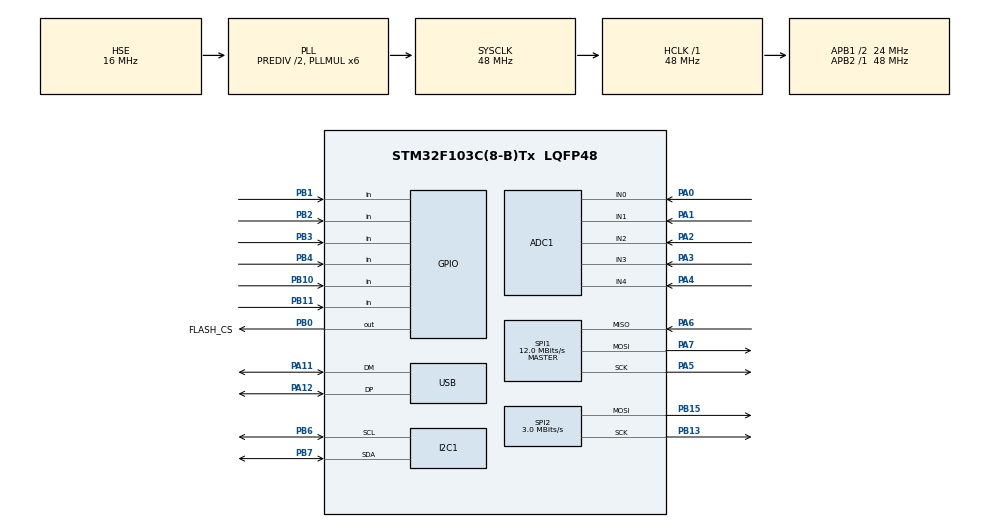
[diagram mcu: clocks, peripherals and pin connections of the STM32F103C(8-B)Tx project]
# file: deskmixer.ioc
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ADC1.Channel-0\#ChannelRegularConversion=ADC_CHANNEL_0
ADC1.NbrOfConversionFlag=1
ADC1.Rank-0\#ChannelRegularConversion=1
ADC1.SamplingTime-0\#ChannelRegularConversion=ADC_SAMPLETIME_1CYCLE_5
ADC1.master=1
Dma.Request0=SPI2_TX
Dma.SPI2_TX.0.Direction=DMA_MEMORY_TO_PERIPH
Dma.SPI2_TX.0.Instance=DMA1_Channel5
Dma.SPI2_TX.0.MemDataAlignment=DMA_MDATAALIGN_BYTE
Dma.SPI2_TX.0.MemInc=DMA_MINC_ENABLE
Dma.SPI2_TX.0.Mode=DMA_NORMAL
Dma.SPI2_TX.0.PeriphDataAlignment=DMA_PDATAALIGN_BYTE
Dma.SPI2_TX.0.PeriphInc=DMA_PINC_DISABLE
Dma.SPI2_TX.0.Priority=DMA_PRIORITY_LOW
Mcu.Family=STM32F1
Mcu.Name=STM32F103C(8-B)Tx
Mcu.Package=LQFP48
NVIC.DMA1_Channel5_IRQn=true\:0\:0\:false\:false\:true\:false\:true\:true
NVIC.PriorityGroup=NVIC_PRIORITYGROUP_4
NVIC.USB_LP_CAN1_RX0_IRQn=true\:0\:0\:false\:false\:true\:false\:true\:true
PA0-WKUP.Signal=ADCx_IN0
PA1.Signal=ADCx_IN1
PA11.Mode=Device
PA11.Signal=USB_DM
PA12.Mode=Device
PA12.Signal=USB_DP
PA13.Mode=Serial_Wire
PA13.Signal=SYS_JTMS-SWDIO
PA14.Mode=Serial_Wire
PA14.Signal=SYS_JTCK-SWCLK
PA2.Signal=ADCx_IN2
PA3.Signal=ADCx_IN3
PA4.Signal=ADCx_IN4
PA5.Mode=Full_Duplex_Master
PA5.Signal=SPI1_SCK
PA6.Mode=Full_Duplex_Master
PA6.Signal=SPI1_MISO
PA7.Mode=Full_Duplex_Master
PA7.Signal=SPI1_MOSI
PB0.GPIO_Label=FLASH_CS
PB0.PinState=GPIO_PIN_SET
PB0.Signal=GPIO_Output
PB1.GPIO_PuPd=GPIO_PULLUP
PB1.Signal=GPIO_Input
PB10.GPIO_PuPd=GPIO_PULLUP
PB10.Signal=GPIO_Input
PB11.GPIO_PuPd=GPIO_PULLUP
PB11.Signal=GPIO_Input
PB13.Mode=TX_Only_Simplex_Unidirect_Master
PB13.Signal=SPI2_SCK
PB15.Mode=TX_Only_Simplex_Unidirect_Master
PB15.Signal=SPI2_MOSI
PB2.GPIO_PuPd=GPIO_PULLUP
PB2.Signal=GPIO_Input
PB3.GPIO_PuPd=GPIO_PULLUP
PB3.Signal=GPIO_Input
PB4.GPIO_PuPd=GPIO_PULLUP
PB4.Signal=GPIO_Input
PB6.Mode=I2C
PB6.Signal=I2C1_SCL
PB7.Mode=I2C
PB7.Signal=I2C1_SDA
PD0-OSC_IN.Mode=HSE-External-Oscillator
PD0-OSC_IN.Signal=RCC_OSC_IN
PD1-OSC_OUT.Mode=HSE-External-Oscillator
PD1-OSC_OUT.Signal=RCC_OSC_OUT
ProjectManager.HeapSize=0x200
ProjectManager.StackSize=0x400
ProjectManager.TargetToolchain=STM32CubeIDE
RCC.ADCPresc=RCC_ADCPCLK2_DIV4
RCC.AHBFreq_Value=48000000
RCC.APB1CLKDivider=RCC_HCLK_DIV2
RCC.APB1Freq_Value=24000000
RCC.APB1TimFreq_Value=48000000
RCC.APB2Freq_Value=48000000
RCC.APB2TimFreq_Value=48000000
RCC.HCLKFreq_Value=48000000
RCC.HSEDivPLL=RCC_HSE_PREDIV_DIV2
RCC.HSE_VALUE=16000000
RCC.PLLMUL=RCC_PLL_MUL6
RCC.SYSCLKFreq_VALUE=48000000
RCC.SYSCLKSource=RCC_SYSCLKSOURCE_PLLCLK
RCC.USBFreq_Value=48000000
SH.ADCx_IN0.0=ADC1_IN0,IN0
SH.ADCx_IN1.0=ADC1_IN1,IN1
SH.ADCx_IN2.0=ADC1_IN2,IN2
SH.ADCx_IN3.0=ADC1_IN3,IN3
SH.ADCx_IN4.0=ADC1_IN4,IN4
SPI1.BaudRatePrescaler=SPI_BAUDRATEPRESCALER_4
SPI1.CalculateBaudRate=12.0 MBits/s
SPI1.Direction=SPI_DIRECTION_2LINES
SPI1.Mode=SPI_MODE_MASTER
SPI1.VirtualType=VM_MASTER
SPI2.BaudRatePrescaler=SPI_BAUDRATEPRESCALER_8
SPI2.CalculateBaudRate=3.0 MBits/s
SPI2.Direction=SPI_DIRECTION_2LINES
SPI2.Mode=SPI_MODE_MASTER
SPI2.VirtualType=VM_MASTER
USB_DEVICE.CLASS_NAME_FS=CDC
USB_DEVICE.VirtualMode=Cdc
USB_DEVICE.VirtualModeFS=Cdc_FS
VP_USB_DEVICE_VS_USB_DEVICE_CDC_FS.Mode=CDC_FS
board=custom

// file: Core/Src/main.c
/* USER CODE BEGIN Header */
/**
  ******************************************************************************
  * @file           : main.c
  * @brief          : Main program body
  ******************************************************************************
  * @attention
  *
  * Copyright (c) 2026 STMicroelectronics.
  * All rights reserved.
  *
  * This software is licensed under terms that can be found in the LICENSE file
  * in the root directory of this software component.
  * If no LICENSE file comes with this software, it is provided AS-IS.
  *
  ******************************************************************************
  */
/* USER CODE END Header */
#include "main.h"
#include "usb_device.h"

/* USER CODE BEGIN Includes */
#include "deskmixer.h"
/* USER CODE END Includes */

ADC_HandleTypeDef hadc1;

I2C_HandleTypeDef hi2c1;

SPI_HandleTypeDef hspi1;
SPI_HandleTypeDef hspi2;
DMA_HandleTypeDef hdma_spi2_tx;

void SystemClock_Config(void);
static void MX_GPIO_Init(void);
static void MX_DMA_Init(void);
static void MX_I2C1_Init(void);
static void MX_SPI1_Init(void);
static void MX_ADC1_Init(void);
static void MX_SPI2_Init(void);

int main(void)
{

  /* MCU Configuration--------------------------------------------------------*/

  /* Reset of all peripherals, Initializes the Flash interface and the Systick. */
  HAL_Init();

  /* Configure the system clock */
  SystemClock_Config();

  /* Initialize all configured peripherals */
  MX_GPIO_Init();
  MX_DMA_Init();
  MX_I2C1_Init();
  MX_SPI1_Init();
  MX_ADC1_Init();
  MX_SPI2_Init();
  MX_USB_DEVICE_Init();
  /* USER CODE BEGIN 2 */
  DESKMIXER_Init();
  /* USER CODE END 2 */

  /* Infinite loop */
  while (1)
  {

    /* USER CODE BEGIN 3 */
    DESKMIXER_Run();
  /* USER CODE END 3 */
  }
}

void SystemClock_Config(void)
{
  RCC_OscInitTypeDef RCC_OscInitStruct = {0};
  RCC_ClkInitTypeDef RCC_ClkInitStruct = {0};
  RCC_PeriphCLKInitTypeDef PeriphClkInit = {0};

  /** Initializes the RCC Oscillators according to the specified parameters
  * in the RCC_OscInitTypeDef structure.
  */
  RCC_OscInitStruct.OscillatorType = RCC_OSCILLATORTYPE_HSE;
  RCC_OscInitStruct.HSEState = RCC_HSE_ON;
  RCC_OscInitStruct.HSEPredivValue = RCC_HSE_PREDIV_DIV2;
  RCC_OscInitStruct.HSIState = RCC_HSI_ON;
  RCC_OscInitStruct.PLL.PLLState = RCC_PLL_ON;
  RCC_OscInitStruct.PLL.PLLSource = RCC_PLLSOURCE_HSE;
  RCC_OscInitStruct.PLL.PLLMUL = RCC_PLL_MUL6;
  if (HAL_RCC_OscConfig(&RCC_OscInitStruct) != HAL_OK)
  {
    Error_Handler();
  }

  /** Initializes the CPU, AHB and APB buses clocks
  */
  RCC_ClkInitStruct.ClockType = RCC_CLOCKTYPE_HCLK|RCC_CLOCKTYPE_SYSCLK
                              |RCC_CLOCKTYPE_PCLK1|RCC_CLOCKTYPE_PCLK2;
  RCC_ClkInitStruct.SYSCLKSource = RCC_SYSCLKSOURCE_PLLCLK;
  RCC_ClkInitStruct.AHBCLKDivider = RCC_SYSCLK_DIV1;
  RCC_ClkInitStruct.APB1CLKDivider = RCC_HCLK_DIV2;
  RCC_ClkInitStruct.APB2CLKDivider = RCC_HCLK_DIV1;

  if (HAL_RCC_ClockConfig(&RCC_ClkInitStruct, FLASH_LATENCY_1) != HAL_OK)
  {
    Error_Handler();
  }
  PeriphClkInit.PeriphClockSelection = RCC_PERIPHCLK_ADC|RCC_PERIPHCLK_USB;
  PeriphClkInit.AdcClockSelection = RCC_ADCPCLK2_DIV4;
  PeriphClkInit.UsbClockSelection = RCC_USBCLKSOURCE_PLL;
  if (HAL_RCCEx_PeriphCLKConfig(&PeriphClkInit) != HAL_OK)
  {
    Error_Handler();
  }
}

static void MX_ADC1_Init(void)
{

  ADC_ChannelConfTypeDef sConfig = {0};

  /** Common config
  */
  hadc1.Instance = ADC1;
  hadc1.Init.ScanConvMode = ADC_SCAN_DISABLE;
  hadc1.Init.ContinuousConvMode = DISABLE;
  hadc1.Init.DiscontinuousConvMode = DISABLE;
  hadc1.Init.ExternalTrigConv = ADC_SOFTWARE_START;
  hadc1.Init.DataAlign = ADC_DATAALIGN_RIGHT;
  hadc1.Init.NbrOfConversion = 1;
  if (HAL_ADC_Init(&hadc1) != HAL_OK)
  {
    Error_Handler();
  }

  /** Configure Regular Channel
  */
  sConfig.Channel = ADC_CHANNEL_0;
  sConfig.Rank = ADC_REGULAR_RANK_1;
  sConfig.SamplingTime = ADC_SAMPLETIME_1CYCLE_5;
  if (HAL_ADC_ConfigChannel(&hadc1, &sConfig) != HAL_OK)
  {
    Error_Handler();
  }

}

static void MX_I2C1_Init(void)
{

  hi2c1.Instance = I2C1;
  hi2c1.Init.ClockSpeed = 100000;
  hi2c1.Init.DutyCycle = I2C_DUTYCYCLE_2;
  hi2c1.Init.OwnAddress1 = 0;
  hi2c1.Init.AddressingMode = I2C_ADDRESSINGMODE_7BIT;
  hi2c1.Init.DualAddressMode = I2C_DUALADDRESS_DISABLE;
  hi2c1.Init.OwnAddress2 = 0;
  hi2c1.Init.GeneralCallMode = I2C_GENERALCALL_DISABLE;
  hi2c1.Init.NoStretchMode = I2C_NOSTRETCH_DISABLE;
  if (HAL_I2C_Init(&hi2c1) != HAL_OK)
  {
    Error_Handler();
  }

}

static void MX_SPI1_Init(void)
{

  /* SPI1 parameter configuration*/
  hspi1.Instance = SPI1;
  hspi1.Init.Mode = SPI_MODE_MASTER;
  hspi1.Init.Direction = SPI_DIRECTION_2LINES;
  hspi1.Init.DataSize = SPI_DATASIZE_8BIT;
  hspi1.Init.CLKPolarity = SPI_POLARITY_LOW;
  hspi1.Init.CLKPhase = SPI_PHASE_1EDGE;
  hspi1.Init.NSS = SPI_NSS_SOFT;
  hspi1.Init.BaudRatePrescaler = SPI_BAUDRATEPRESCALER_4;
  hspi1.Init.FirstBit = SPI_FIRSTBIT_MSB;
  hspi1.Init.TIMode = SPI_TIMODE_DISABLE;
  hspi1.Init.CRCCalculation = SPI_CRCCALCULATION_DISABLE;
  hspi1.Init.CRCPolynomial = 10;
  if (HAL_SPI_Init(&hspi1) != HAL_OK)
  {
    Error_Handler();
  }

}

static void MX_SPI2_Init(void)
{

  /* SPI2 parameter configuration*/
  hspi2.Instance = SPI2;
  hspi2.Init.Mode = SPI_MODE_MASTER;
  hspi2.Init.Direction = SPI_DIRECTION_2LINES;
  hspi2.Init.DataSize = SPI_DATASIZE_8BIT;
  hspi2.Init.CLKPolarity = SPI_POLARITY_LOW;
  hspi2.Init.CLKPhase = SPI_PHASE_1EDGE;
  hspi2.Init.NSS = SPI_NSS_SOFT;
  hspi2.Init.BaudRatePrescaler = SPI_BAUDRATEPRESCALER_8;
  hspi2.Init.FirstBit = SPI_FIRSTBIT_MSB;
  hspi2.Init.TIMode = SPI_TIMODE_DISABLE;
  hspi2.Init.CRCCalculation = SPI_CRCCALCULATION_DISABLE;
  hspi2.Init.CRCPolynomial = 10;
  if (HAL_SPI_Init(&hspi2) != HAL_OK)
  {
    Error_Handler();
  }

}

static void MX_DMA_Init(void)
{

  /* DMA controller clock enable */
  __HAL_RCC_DMA1_CLK_ENABLE();

  /* DMA interrupt init */
  /* DMA1_Channel5_IRQn interrupt configuration */
  HAL_NVIC_SetPriority(DMA1_Channel5_IRQn, 0, 0);
  HAL_NVIC_EnableIRQ(DMA1_Channel5_IRQn);

}

static void MX_GPIO_Init(void)
{
  GPIO_InitTypeDef GPIO_InitStruct = {0};

  /* GPIO Ports Clock Enable */
  __HAL_RCC_GPIOD_CLK_ENABLE();
  __HAL_RCC_GPIOA_CLK_ENABLE();
  __HAL_RCC_GPIOB_CLK_ENABLE();

  /*Configure GPIO pin Output Level */
  HAL_GPIO_WritePin(FLASH_CS_GPIO_Port, FLASH_CS_Pin, GPIO_PIN_SET);

  /*Configure GPIO pin : FLASH_CS_Pin */
  GPIO_InitStruct.Pin = FLASH_CS_Pin;
  GPIO_InitStruct.Mode = GPIO_MODE_OUTPUT_PP;
  GPIO_InitStruct.Pull = GPIO_NOPULL;
  GPIO_InitStruct.Speed = GPIO_SPEED_FREQ_LOW;
  HAL_GPIO_Init(FLASH_CS_GPIO_Port, &GPIO_InitStruct);

  /*Configure GPIO pins : PB1 PB2 PB10 PB11
                           PB3 PB4 */
  GPIO_InitStruct.Pin = GPIO_PIN_1|GPIO_PIN_2|GPIO_PIN_10|GPIO_PIN_11
                          |GPIO_PIN_3|GPIO_PIN_4;
  GPIO_InitStruct.Mode = GPIO_MODE_INPUT;
  GPIO_InitStruct.Pull = GPIO_PULLUP;
  HAL_GPIO_Init(GPIOB, &GPIO_InitStruct);

}

void Error_Handler(void)
{
  __disable_irq();
  while (1)
  {
  }
}
